# ATSAMA5D33 register map
Vendor: Atmel; Series: SAMA5D3; File version: 20130221
Registers are 32-bit, read-write, reset 0x0 unless marked. A register's access mark holds for its fields unless they carry their own. Offsets are from the block's base; [hi:lo] are bit positions; {n}, {i} and the like mark numbered series; 'fields as' and 'values as' point back to an identical list.

## SPI0 — Serial Peripheral Interface 0
Base 0xF0004000; register names take the prefix SPI0_
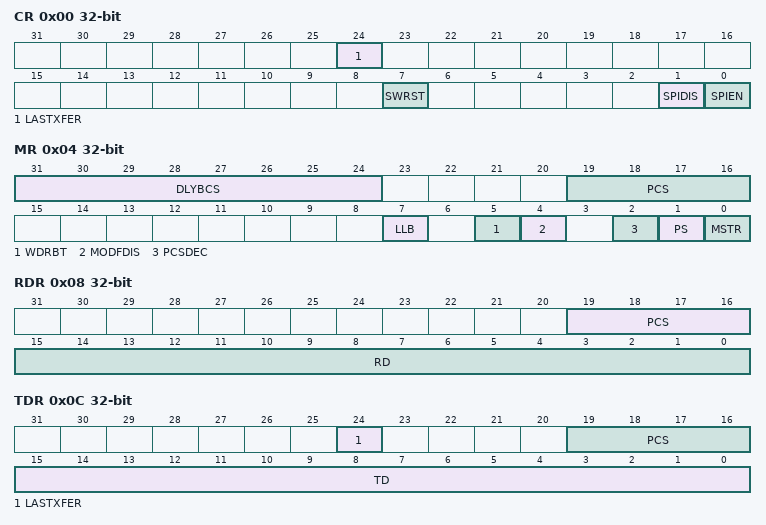
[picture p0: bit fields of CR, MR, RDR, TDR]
0x00 CR wo reset not defined — Control Register
  [24] LASTXFER — Last Transfer
  [7] SWRST — SPI Software Reset
  [1] SPIDIS — SPI Disable
  [0] SPIEN — SPI Enable
0x04 MR — Mode Register
  [31:24] DLYBCS — Delay Between Chip Selects
  [19:16] PCS — Peripheral Chip Select
  [7] LLB — Local Loopback Enable
  [5] WDRBT — Wait Data Read Before Transfer
  [4] MODFDIS — Mode Fault Detection
  [2] PCSDEC — Chip Select Decode
  [1] PS — Peripheral Select
  [0] MSTR — Master/Slave Mode
0x08 RDR ro — Receive Data Register
  [19:16] PCS — Peripheral Chip Select
  [15:0] RD — Receive Data
0x0C TDR wo reset not defined — Transmit Data Register
  [24] LASTXFER — Last Transfer
  [19:16] PCS — Peripheral Chip Select
  [15:0] TD — Transmit Data
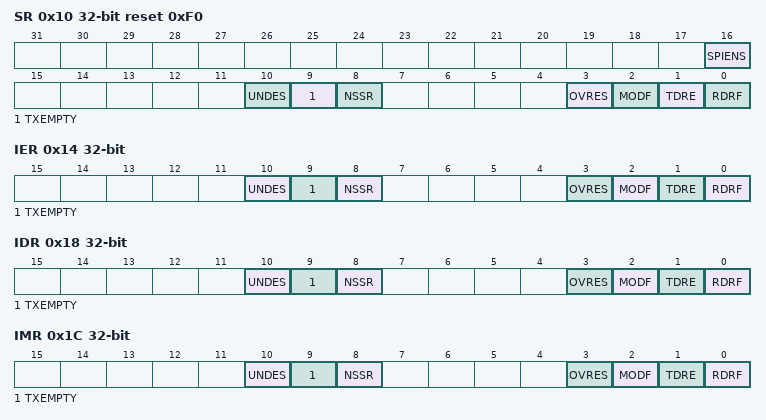
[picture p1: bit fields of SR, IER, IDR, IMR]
0x10 SR ro reset 0xF0 — Status Register
  [16] SPIENS — SPI Enable Status
  [10] UNDES — Underrun Error Status (Slave Mode Only)
  [9] TXEMPTY — Transmission Registers Empty
  [8] NSSR — NSS Rising
  [3] OVRES — Overrun Error Status
  [2] MODF — Mode Fault Error
  [1] TDRE — Transmit Data Register Empty
  [0] RDRF — Receive Data Register Full
0x14 IER wo reset not defined — Interrupt Enable Register
  [10] UNDES — Underrun Error Interrupt Enable
  [9] TXEMPTY — Transmission Registers Empty Enable
  [8] NSSR — NSS Rising Interrupt Enable
  [3] OVRES — Overrun Error Interrupt Enable
  [2] MODF — Mode Fault Error Interrupt Enable
  [1] TDRE — SPI Transmit Data Register Empty Interrupt Enable
  [0] RDRF — Receive Data Register Full Interrupt Enable
0x18 IDR wo reset not defined — Interrupt Disable Register
  [10] UNDES — Underrun Error Interrupt Disable
  [9] TXEMPTY — Transmission Registers Empty Disable
  [8] NSSR — NSS Rising Interrupt Disable
  [3] OVRES — Overrun Error Interrupt Disable
  [2] MODF — Mode Fault Error Interrupt Disable
  [1] TDRE — SPI Transmit Data Register Empty Interrupt Disable
  [0] RDRF — Receive Data Register Full Interrupt Disable
0x1C IMR ro — Interrupt Mask Register
  [10] UNDES — Underrun Error Interrupt Mask
  [9] TXEMPTY — Transmission Registers Empty Mask
  [8] NSSR — NSS Rising Interrupt Mask
  [3] OVRES — Overrun Error Interrupt Mask
  [2] MODF — Mode Fault Error Interrupt Mask
  [1] TDRE — SPI Transmit Data Register Empty Interrupt Mask
  [0] RDRF — Receive Data Register Full Interrupt Mask
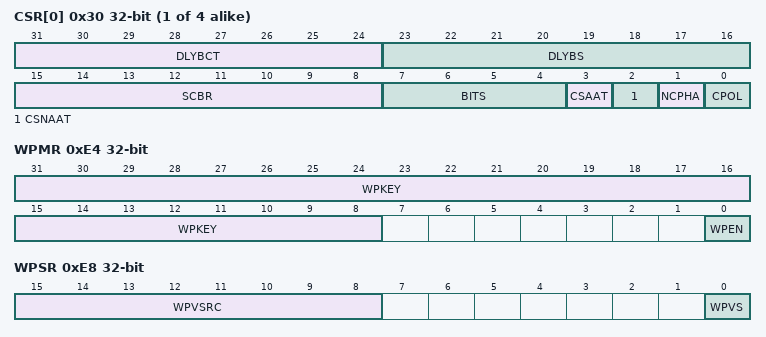
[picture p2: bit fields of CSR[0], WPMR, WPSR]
{0x30+4i} CSR[{i}] (i=0..3) reset not defined — Chip Select Register
  [31:24] DLYBCT — Delay Between Consecutive Transfers
  [23:16] DLYBS — Delay Before SPCK
  [15:8] SCBR — Serial Clock Baud Rate
  [7:4] BITS — Bits Per Transfer
    {v}={v+8}_BIT ({v+8} bits for transfer) (v=0..8)
  [3] CSAAT — Chip Select Active After Transfer
  [2] CSNAAT — Chip Select Not Active After Transfer (Ignored if CSAAT = 1)
  [1] NCPHA — Clock Phase
  [0] CPOL — Clock Polarity
0xE4 WPMR — Write Protection Control Register
  [31:8] WPKEY — Write Protection Key Password
  [0] WPEN — Write Protection Enable
0xE8 WPSR ro — Write Protection Status Register
  [15:8] WPVSRC — Write Protection Violation Source
  [0] WPVS — Write Protection Violation Status

## SPI1 — Serial Peripheral Interface 1
Base 0xF8008000; register names take the prefix SPI1_
Registers as SPI0.

## SFR — Special Function Registers
Base 0xF0038000; register names take the prefix SFR_
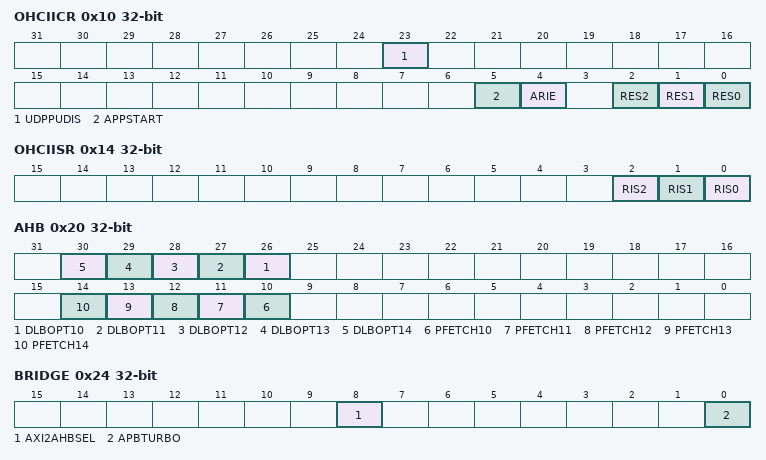
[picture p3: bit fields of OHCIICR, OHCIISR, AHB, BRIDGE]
0x10 OHCIICR — OHCI Interrupt Configuration Register
  [23] UDPPUDIS — OHCI USB DEVICE PULL-UP DISABLE
  [5] APPSTART — Reserved
  [4] ARIE — OHCI Asynchronous Resume Interrupt Enable
  [2] RES2 — USB PORTx RESET
  [1] RES1 — USB PORTx RESET
  [0] RES0 — USB PORTx RESET
0x14 OHCIISR ro reset not defined — OHCI Interrupt Status Register
  [2] RIS2 — OHCI Resume Interrupt Status Port 2
  [1] RIS1 — OHCI Resume Interrupt Status Port 1
  [0] RIS0 — OHCI Resume Interrupt Status Port 0
0x20 AHB — AHB Configuration Register
  [n+16] DLBOPT{n} (n=10..14) — AHB MASTERx {n} Converter Define Length Burst Optimization
  [n] PFETCH{n} (n=10..14) — AHB MASTERx {n} Converter Prefetch
    0=INCR4 (INCR undefined burst converted to burst of 4 beats.); 1=INCR8 (INCR undefined burst converted to burst of 8 beats.)
0x24 BRIDGE — Bridge Configuration Register
  [8] AXI2AHBSEL — AXI to AHB bridge for DDR controller selection
    0=SINGLE (use single port bridge.); 1=DUAL (use dual port bridge.)
  [0] APBTURBO — AHB to APB Bridge mode
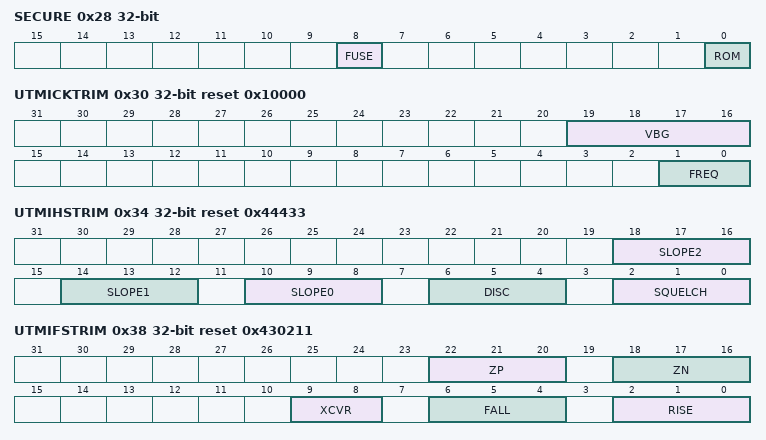
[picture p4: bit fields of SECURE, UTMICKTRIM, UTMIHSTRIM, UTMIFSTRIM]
0x28 SECURE — Security Configuration Register
  [8] FUSE — Disable Access to Fuse Controller
  [0] ROM — Disable Access to ROM Code
0x30 UTMICKTRIM reset 0x10000 — UTMI Clock Trimming Register
  [19:16] VBG — UTMI Band Gap Voltage Trimming
  [1:0] FREQ — UTMI Reference Clock Frequency
    0=12 MHz reference clock; 1=16 MHz reference clock; 2=24 MHz reference clock; 3=48 MHz reference clock
0x34 UTMIHSTRIM reset 0x44433 — UTMI High Speed Trimming Register
  [18:16] SLOPE2 — UTMI HS PORTx Transceiver Slope Trimming
  [14:12] SLOPE1 — UTMI HS PORTx Transceiver Slope Trimming
  [10:8] SLOPE0 — UTMI HS PORTx Transceiver Slope Trimming
  [6:4] DISC — UTMI Disconnect Voltage Trimming
  [2:0] SQUELCH — UTMI HS SQUELCH Voltage Trimming
0x38 UTMIFSTRIM reset 0x430211 — UTMI Full Speed Trimming Register
  [22:20] ZP — FS Transceiver PMOS impedance trimming
  [18:16] ZN — FS Transceiver NMOS impedance trimming
  [9:8] XCVR — FS Transceiver crossover voltage trimming
  [6:4] FALL — FS Transceiver output falling slope trimming
  [2:0] RISE — FS Transceiver output rising slope trimming
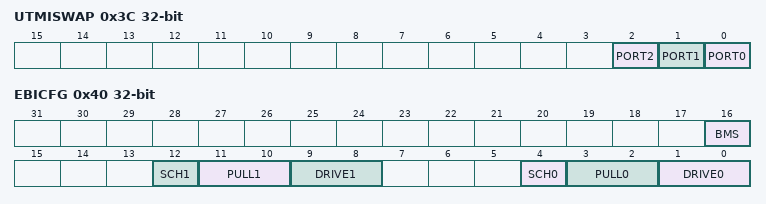
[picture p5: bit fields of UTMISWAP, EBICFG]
0x3C UTMISWAP — UTMI DP/DM Pin Swapping Register
  [all] fields
    0=NORMAL (DP/DM normal pinout.); 1=SWAPPED (DP/DM swapped pinout.)
  [2] PORT2 — PORT 2 DP/DM Pin Swapping
  [1] PORT1 — PORT 1 DP/DM Pin Swapping
  [0] PORT0 — PORT 0 DP/DM Pin Swapping
0x40 EBICFG reset not defined — EBI Configuration Register
  [16] BMS — BMS Sampled Value (Read Only)
    0=ROM (Boot on ROM.); 1=EBI (Boot on EBI.)
  [12] SCH1 — EBI Pins Schmitt Trigger
  [11:10] PULL1 — EBI Pins Pull Value
    0=UP (Pull-up); 1=NONE (No Pull); 3=DOWN (Pull-down)
  [9:8] DRIVE1 — EBI Pins Drive Level
    0=LOW (Low drive level); 2=MEDIUM (Medium drive level); 3=HIGH (High drive level)
  [4] SCH0 — EBI Pins Schmitt Trigger
  [3:2] PULL0 — EBI Pins Pull Value
    0=UP (Pull-up); 1=NONE (No Pull); 3=DOWN (Pull-down)
  [1:0] DRIVE0 — EBI Pins Drive Level
    values as DRIVE1

## Notices in the file
SAM Software Package License
Copyright (c) 2013, Atmel Corporation
All rights reserved.
Redistribution and use in source and binary forms, with or without
modification, are permitted provided that the following condition is met:
- Redistributions of source code must retain the above copyright notice,
this list of conditions and the disclaimer below.
Atmel's name may not be used to endorse or promote products derived from
this software without specific prior written permission.
DISCLAIMER:  THIS SOFTWARE IS PROVIDED BY ATMEL "AS IS" AND ANY EXPRESS OR
IMPLIED WARRANTIES, INCLUDING, BUT NOT LIMITED TO, THE IMPLIED WARRANTIES OF
MERCHANTABILITY, FITNESS FOR A PARTICULAR PURPOSE AND NON-INFRINGEMENT ARE
DISCLAIMED. IN NO EVENT SHALL ATMEL BE LIABLE FOR ANY DIRECT, INDIRECT,
INCIDENTAL, SPECIAL, EXEMPLARY, OR CONSEQUENTIAL DAMAGES (INCLUDING, BUT NOT
LIMITED TO, PROCUREMENT OF SUBSTITUTE GOODS OR SERVICES; LOSS OF USE, DATA,
OR PROFITS; OR BUSINESS INTERRUPTION) HOWEVER CAUSED AND ON ANY THEORY OF
LIABILITY, WHETHER IN CONTRACT, STRICT LIABILITY, OR TORT (INCLUDING
NEGLIGENCE OR OTHERWISE) ARISING IN ANY WAY OUT OF THE USE OF THIS SOFTWARE,
EVEN IF ADVISED OF THE POSSIBILITY OF SUCH DAMAGE.
